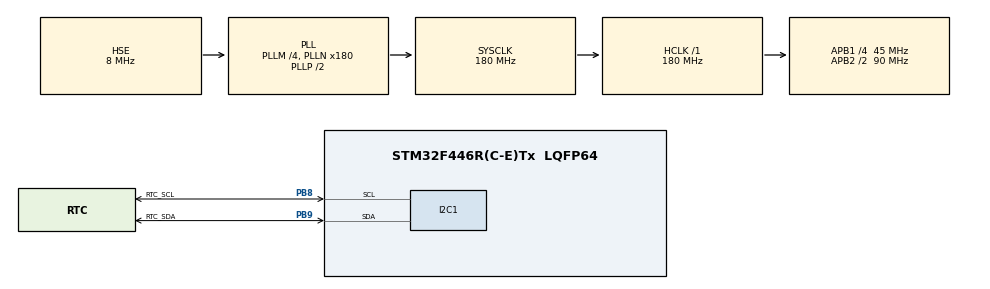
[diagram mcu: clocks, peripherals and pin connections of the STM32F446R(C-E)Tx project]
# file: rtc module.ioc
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Mcu.Family=STM32F4
Mcu.Name=STM32F446R(C-E)Tx
Mcu.Package=LQFP64
NVIC.PriorityGroup=NVIC_PRIORITYGROUP_0
PA13.Mode=Serial_Wire
PA13.Signal=SYS_JTMS-SWDIO
PA14.Mode=Serial_Wire
PA14.Signal=SYS_JTCK-SWCLK
PB8.GPIO_Label=RTC_SCL
PB8.Mode=I2C
PB8.Signal=I2C1_SCL
PB9.GPIO_Label=RTC_SDA
PB9.Mode=I2C
PB9.Signal=I2C1_SDA
PC14-OSC32_IN.Mode=LSE-External-Oscillator
PC14-OSC32_IN.Signal=RCC_OSC32_IN
PC15-OSC32_OUT.Mode=LSE-External-Oscillator
PC15-OSC32_OUT.Signal=RCC_OSC32_OUT
PH0-OSC_IN.Mode=HSE-External-Oscillator
PH0-OSC_IN.Signal=RCC_OSC_IN
PH1-OSC_OUT.Mode=HSE-External-Oscillator
PH1-OSC_OUT.Signal=RCC_OSC_OUT
ProjectManager.HeapSize=0x200
ProjectManager.StackSize=0x400
ProjectManager.TargetToolchain=STM32CubeIDE
RCC.48MHZClocksFreq_Value=84000000
RCC.AHBFreq_Value=180000000
RCC.APB1CLKDivider=RCC_HCLK_DIV4
RCC.APB1Freq_Value=45000000
RCC.APB1TimFreq_Value=90000000
RCC.APB2CLKDivider=RCC_HCLK_DIV2
RCC.APB2Freq_Value=90000000
RCC.APB2TimFreq_Value=180000000
RCC.CortexFreq_Value=180000000
RCC.FLatency-AdvancedSettings=FLASH_LATENCY_5
RCC.HCLKFreq_Value=180000000
RCC.HSE_VALUE=8000000
RCC.HSI_VALUE=16000000
RCC.PLLM=4
RCC.PLLN=180
RCC.PLLSourceVirtual=RCC_PLLSOURCE_HSE
RCC.SYSCLKFreq_VALUE=180000000
RCC.SYSCLKSource=RCC_SYSCLKSOURCE_PLLCLK
RCC.USBFreq_Value=180000000
RCC.VCOOutputFreq_Value=360000000
board=NUCLEO-F446RE

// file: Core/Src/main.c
/* USER CODE BEGIN Header */
/**
  ******************************************************************************
  * @file           : main.c
  * @brief          : Main program body
  ******************************************************************************
  * @attention
  *
  * Copyright (c) 2023 STMicroelectronics.
  * All rights reserved.
  *
  * This software is licensed under terms that can be found in the LICENSE file
  * in the root directory of this software component.
  * If no LICENSE file comes with this software, it is provided AS-IS.
  *
  ******************************************************************************
  */
/* USER CODE END Header */
#include "main.h"

/* USER CODE BEGIN Includes */
#include "stdio.h"
/* USER CODE END Includes */

I2C_HandleTypeDef hi2c1;

void SystemClock_Config(void);
static void MX_GPIO_Init(void);
static void MX_I2C1_Init(void);

/* USER CODE BEGIN 0 */
#define DS3231_ADDRESS 0xD0
// Convert normal decimal numbers to binary coded decimal
uint8_t decToBcd(int val)
{
  return (uint8_t)( (val/10*16) + (val%10) );
}
// Convert binary coded decimal to normal decimal numbers
int bcdToDec(uint8_t val)
{
  return (int)( (val/16*10) + (val%16) );
}

typedef struct {
	uint8_t seconds;
	uint8_t minutes;
	uint8_t hour;
	uint8_t dayofweek;
	uint8_t dayofmonth;
	uint8_t month;
	uint8_t year;
} TIME;

TIME time;

// function to set time
//void Backup()
//{
//
//	HAL_I2C_Mem_Read(&hi2c1, DS3231_ADDRESS, 0x00, 1, Backup, 7, 1000);
//	Set_Time();
//}
void Set_Time (uint8_t sec, uint8_t min, uint8_t hour, uint8_t dow, uint8_t dom, uint8_t month, uint8_t year)
{
	uint8_t set_time[7];
	set_time[0] = decToBcd(sec);
	set_time[1] = decToBcd(min);
	set_time[2] = decToBcd(hour);
	set_time[3] = decToBcd(dow);
	set_time[4] = decToBcd(dom);
	set_time[5] = decToBcd(month);
	set_time[6] = decToBcd(year);
	HAL_I2C_Mem_Write(&hi2c1, DS3231_ADDRESS, 0x00, 1, set_time, 7, 1000);
}
void Get_Time (void)
{
	uint8_t get_time[7];
	HAL_I2C_Mem_Read(&hi2c1, DS3231_ADDRESS, 0x00, 1, get_time, 7, 1000);
	time.seconds = bcdToDec(get_time[0]);
	time.minutes = bcdToDec(get_time[1]);
	time.hour = bcdToDec(get_time[2]);
	time.dayofweek = bcdToDec(get_time[3]);
	time.dayofmonth = bcdToDec(get_time[4]);
	time.month = bcdToDec(get_time[5]);
	time.year = bcdToDec(get_time[6]);
}

//char buffer[15];

/* USER CODE END 0 */

int main(void)
{

  /* MCU Configuration--------------------------------------------------------*/

  /* Reset of all peripherals, Initializes the Flash interface and the Systick. */
  HAL_Init();

  /* Configure the system clock */
  SystemClock_Config();

  /* Initialize all configured peripherals */
  MX_GPIO_Init();
  MX_I2C1_Init();
  /* USER CODE BEGIN 2 */
    Set_Time(1, 48, 15, 4, 4, 6, 23);
  /* USER CODE END 2 */

  /* Infinite loop */
  while (1)
  {

    /* USER CODE BEGIN 3 */
	  Get_Time();
	  HAL_Delay(500);
  }
//  Backup();
  /* USER CODE END 3 */
}

void SystemClock_Config(void)
{
  RCC_OscInitTypeDef RCC_OscInitStruct = {0};
  RCC_ClkInitTypeDef RCC_ClkInitStruct = {0};

  /** Configure the main internal regulator output voltage
  */
  __HAL_RCC_PWR_CLK_ENABLE();
  __HAL_PWR_VOLTAGESCALING_CONFIG(PWR_REGULATOR_VOLTAGE_SCALE1);

  /** Initializes the RCC Oscillators according to the specified parameters
  * in the RCC_OscInitTypeDef structure.
  */
  RCC_OscInitStruct.OscillatorType = RCC_OSCILLATORTYPE_HSE;
  RCC_OscInitStruct.HSEState = RCC_HSE_ON;
  RCC_OscInitStruct.PLL.PLLState = RCC_PLL_ON;
  RCC_OscInitStruct.PLL.PLLSource = RCC_PLLSOURCE_HSE;
  RCC_OscInitStruct.PLL.PLLM = 4;
  RCC_OscInitStruct.PLL.PLLN = 180;
  RCC_OscInitStruct.PLL.PLLP = RCC_PLLP_DIV2;
  RCC_OscInitStruct.PLL.PLLQ = 2;
  RCC_OscInitStruct.PLL.PLLR = 2;
  if (HAL_RCC_OscConfig(&RCC_OscInitStruct) != HAL_OK)
  {
    Error_Handler();
  }

  /** Activate the Over-Drive mode
  */
  if (HAL_PWREx_EnableOverDrive() != HAL_OK)
  {
    Error_Handler();
  }

  /** Initializes the CPU, AHB and APB buses clocks
  */
  RCC_ClkInitStruct.ClockType = RCC_CLOCKTYPE_HCLK|RCC_CLOCKTYPE_SYSCLK
                              |RCC_CLOCKTYPE_PCLK1|RCC_CLOCKTYPE_PCLK2;
  RCC_ClkInitStruct.SYSCLKSource = RCC_SYSCLKSOURCE_PLLCLK;
  RCC_ClkInitStruct.AHBCLKDivider = RCC_SYSCLK_DIV1;
  RCC_ClkInitStruct.APB1CLKDivider = RCC_HCLK_DIV4;
  RCC_ClkInitStruct.APB2CLKDivider = RCC_HCLK_DIV2;

  if (HAL_RCC_ClockConfig(&RCC_ClkInitStruct, FLASH_LATENCY_5) != HAL_OK)
  {
    Error_Handler();
  }
}

static void MX_I2C1_Init(void)
{

  hi2c1.Instance = I2C1;
  hi2c1.Init.ClockSpeed = 100000;
  hi2c1.Init.DutyCycle = I2C_DUTYCYCLE_2;
  hi2c1.Init.OwnAddress1 = 0;
  hi2c1.Init.AddressingMode = I2C_ADDRESSINGMODE_7BIT;
  hi2c1.Init.DualAddressMode = I2C_DUALADDRESS_DISABLE;
  hi2c1.Init.OwnAddress2 = 0;
  hi2c1.Init.GeneralCallMode = I2C_GENERALCALL_DISABLE;
  hi2c1.Init.NoStretchMode = I2C_NOSTRETCH_DISABLE;
  if (HAL_I2C_Init(&hi2c1) != HAL_OK)
  {
    Error_Handler();
  }

}

static void MX_GPIO_Init(void)
{

  /* GPIO Ports Clock Enable */
  __HAL_RCC_GPIOC_CLK_ENABLE();
  __HAL_RCC_GPIOH_CLK_ENABLE();
  __HAL_RCC_GPIOA_CLK_ENABLE();
  __HAL_RCC_GPIOB_CLK_ENABLE();

}

void Error_Handler(void)
{
  __disable_irq();
  while (1)
  {
  }
}
